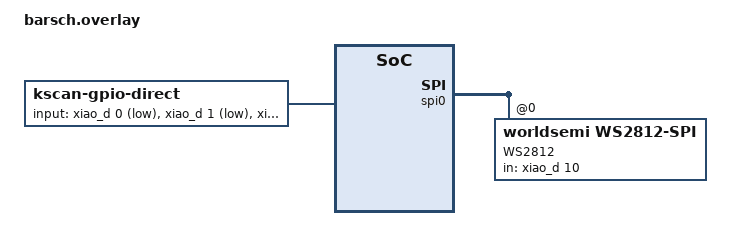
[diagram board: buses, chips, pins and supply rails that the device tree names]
#include <dt-bindings/gpio/gpio.h>
/ {
    chosen {
        zmk,kscan = &kscan0;
        zmk,underglow = &led_strip;
    };

    kscan0: kscan {
        compatible = "zmk,kscan-gpio-direct";
        label = "KSCAN";
        /* D0-D4 = Taster, D7 = BT-Host, D8 = Layer-Mod */
        input-gpios = <&xiao_d 0 (GPIO_ACTIVE_LOW | GPIO_PULL_UP)>,
                      <&xiao_d 1 (GPIO_ACTIVE_LOW | GPIO_PULL_UP)>,
                      <&xiao_d 2 (GPIO_ACTIVE_LOW | GPIO_PULL_UP)>,
                      <&xiao_d 3 (GPIO_ACTIVE_LOW | GPIO_PULL_UP)>,
                      <&xiao_d 4 (GPIO_ACTIVE_LOW | GPIO_PULL_UP)>,
                      <&xiao_d 7 (GPIO_ACTIVE_LOW | GPIO_PULL_UP)>,
                      <&xiao_d 8 (GPIO_ACTIVE_LOW | GPIO_PULL_UP)>;
    };
};
#include <dt-bindings/led/led.h>
&spi0 {
    compatible = "nordic,nrf-spim";
    status = "okay";
    
    led_strip: ws2812@0 {
        compatible = "worldsemi,ws2812-spi";
        label = "WS2812";
        in-gpios = <&xiao_d 10 0>;
        spi-bus = <0>;
        chain-length = <2>;
        color-mapping = <LED_COLOR_ID_GRB>;
    };
};
